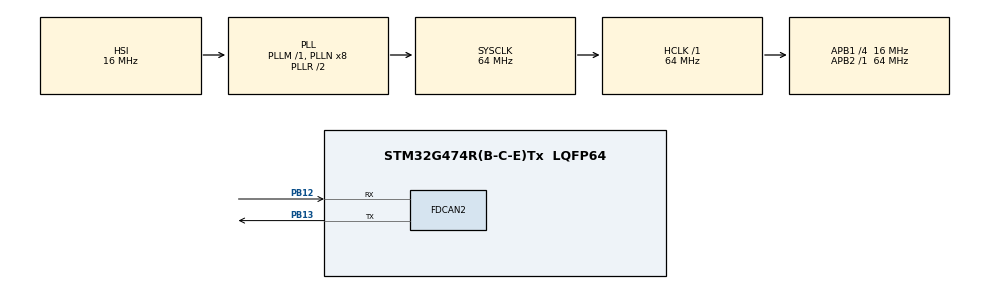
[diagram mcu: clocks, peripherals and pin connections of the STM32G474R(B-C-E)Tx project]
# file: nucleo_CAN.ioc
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FDCAN2.CalculateBaudRateNominal=500000
FDCAN2.CalculateTimeBitNominal=2000
FDCAN2.CalculateTimeQuantumNominal=125.0
FDCAN2.NominalPrescaler=2
FDCAN2.NominalTimeSeg1=13
FDCAN2.NominalTimeSeg2=2
Mcu.Family=STM32G4
Mcu.Name=STM32G474R(B-C-E)Tx
Mcu.Package=LQFP64
NUCLEO-G474RE.BUTTON=1
NUCLEO-G474RE.LD2=true
NUCLEO-G474RE.VCP=true
NVIC.EXTI15_10_IRQn=true\:0\:0\:false\:false\:true\:false\:true\:true
NVIC.PriorityGroup=NVIC_PRIORITYGROUP_4
PA13.GPIO_Label=T_SWDIO
PA13.Signal=SYS_JTMS-SWDIO
PA14.GPIO_Label=T_SWCLK
PA14.Signal=SYS_JTCK-SWCLK
PA2.Signal=LPUART1_TX
PA3.Signal=LPUART1_RX
PB12.Mode=FDCAN_Activate
PB12.Signal=FDCAN2_RX
PB13.Mode=FDCAN_Activate
PB13.Signal=FDCAN2_TX
PB3.GPIO_Label=T_SWO
PB3.Signal=SYS_JTDO-SWO
PC14-OSC32_IN.GPIO_Label=RCC_OSC32_IN
PC14-OSC32_IN.Signal=RCC_OSC32_IN
PC15-OSC32_OUT.GPIO_Label=RCC_OSC32_OUT
PC15-OSC32_OUT.Signal=RCC_OSC32_OUT
PF0-OSC_IN.GPIO_Label=RCC_OSC_IN
PF0-OSC_IN.Signal=RCC_OSC_IN
PF1-OSC_OUT.GPIO_Label=RCC_OSC_OUT
PF1-OSC_OUT.Signal=RCC_OSC_OUT
ProjectManager.HeapSize=0x200
ProjectManager.StackSize=0x400
ProjectManager.TargetToolchain=STM32CubeIDE
RCC.ADC12Freq_Value=64000000
RCC.ADC345Freq_Value=64000000
RCC.AHBFreq_Value=64000000
RCC.APB1CLKDivider=RCC_HCLK_DIV4
RCC.APB1Freq_Value=16000000
RCC.APB1TimFreq_Value=32000000
RCC.APB2Freq_Value=64000000
RCC.APB2TimFreq_Value=64000000
RCC.CortexFreq_Value=64000000
RCC.EXTERNAL_CLOCK_VALUE=12288000
RCC.HCLKFreq_Value=64000000
RCC.HSE_VALUE=24000000
RCC.HSI48_VALUE=48000000
RCC.HSI_VALUE=16000000
RCC.LSE_VALUE=32768
RCC.RTCClockSelection=RCC_RTCCLKSOURCE_LSE
RCC.SYSCLKFreq_VALUE=64000000
RCC.SYSCLKSource=RCC_SYSCLKSOURCE_PLLCLK
RCC.USBFreq_Value=64000000
RCC.VCOOutputFreq_Value=128000000
VP_NUCLEO-G474RE_VS_BSP_COMMON.Mode=COMMON
VP_SYS_VS_DBSignals.Mode=DisableDeadBatterySignals
board=NUCLEO-G474RE

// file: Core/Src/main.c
/* USER CODE BEGIN Header */
/**
  ******************************************************************************
  * @file           : main.c
  * @brief          : Main program body
  ******************************************************************************
  * @attention
  *
  * Copyright (c) 2026 STMicroelectronics.
  * All rights reserved.
  *
  * This software is licensed under terms that can be found in the LICENSE file
  * in the root directory of this software component.
  * If no LICENSE file comes with this software, it is provided AS-IS.
  *
  ******************************************************************************
  */
/* USER CODE END Header */
#include "main.h"

/* USER CODE BEGIN Includes */

#include <stdio.h>
#include <string.h>
/* USER CODE END Includes */

COM_InitTypeDef BspCOMInit;
FDCAN_HandleTypeDef hfdcan2;

/* USER CODE BEGIN PV */
FDCAN_TxHeaderTypeDef TxHeader;
uint8_t TxData[8] = {0};
uint8_t counter = 0;
/* USER CODE END PV */

void SystemClock_Config(void);
static void MX_GPIO_Init(void);
static void MX_FDCAN2_Init(void);

int main(void)
{

  /* MCU Configuration--------------------------------------------------------*/

  /* Reset of all peripherals, Initializes the Flash interface and the Systick. */
  HAL_Init();

  /* Configure the system clock */
  SystemClock_Config();

  /* Initialize all configured peripherals */
  MX_GPIO_Init();
  MX_FDCAN2_Init();
  /* USER CODE BEGIN 2 */
  HAL_Delay(3000);  /* let USB CDC enumerate */

    TxHeader.Identifier          = 0x100;
    TxHeader.IdType              = FDCAN_STANDARD_ID;
    TxHeader.TxFrameType         = FDCAN_DATA_FRAME;
    TxHeader.DataLength          = FDCAN_DLC_BYTES_8;
    TxHeader.ErrorStateIndicator = FDCAN_ESI_ACTIVE;
    TxHeader.BitRateSwitch       = FDCAN_BRS_OFF;
    TxHeader.FDFormat            = FDCAN_CLASSIC_CAN;
    TxHeader.TxEventFifoControl  = FDCAN_NO_TX_EVENTS;
    TxHeader.MessageMarker       = 0;

    if (HAL_FDCAN_Start(&hfdcan2) != HAL_OK) {
      printf("FAIL: FDCAN Start\r\n");
      HAL_Delay(100);
    } else {
      printf("FDCAN2 started — transmitting...\r\n");
      HAL_Delay(100);
    }
  /* USER CODE END 2 */

  /* Initialize led */
  BSP_LED_Init(LED_GREEN);

  /* Initialize USER push-button, will be used to trigger an interrupt each time it's pressed.*/
  BSP_PB_Init(BUTTON_USER, BUTTON_MODE_EXTI);

  /* Initialize COM1 port (115200, 8 bits (7-bit data + 1 stop bit), no parity */
  BspCOMInit.BaudRate   = 115200;
  BspCOMInit.WordLength = COM_WORDLENGTH_8B;
  BspCOMInit.StopBits   = COM_STOPBITS_1;
  BspCOMInit.Parity     = COM_PARITY_NONE;
  BspCOMInit.HwFlowCtl  = COM_HWCONTROL_NONE;
  if (BSP_COM_Init(COM1, &BspCOMInit) != BSP_ERROR_NONE)
  {
    Error_Handler();
  }

  /* Infinite loop */
  while (1)
  {

    /* USER CODE BEGIN 3 */
	  /* Fill dummy data — byte 0 counts up so you can see it changing */
	  	  	    TxData[0] = counter;
	  	  	    TxData[1] = 0xAA;
	  	  	    TxData[2] = 0xBB;
	  	  	    TxData[3] = 0xCC;
	  	  	    TxData[4] = 0xDD;
	  	  	    TxData[5] = 0xEE;
	  	  	    TxData[6] = 0xFF;
	  	  	    TxData[7] = counter;

	  	  	    /* Attempt to send */

	  	  	    HAL_StatusTypeDef whatsTheError = HAL_FDCAN_AddMessageToTxFifoQ(&hfdcan2, &TxHeader, TxData);
	  	  	    printf("%d\r\n", whatsTheError);

	  	  	    if (whatsTheError == HAL_OK) {
	  	  	      printf("TX OK  | counter=%d\r\n", counter);
	  	  	    } else {
	  	  	    	printf("TX FAIL| counter=%d\r\n", counter);
	  	  	    }

	  	  	    counter++;
	  	  	    HAL_Delay(500);  /* Send every 500 ms */

	    }
  }
  /* USER CODE END 3 */

void SystemClock_Config(void)
{
  RCC_OscInitTypeDef RCC_OscInitStruct = {0};
  RCC_ClkInitTypeDef RCC_ClkInitStruct = {0};

  /** Configure the main internal regulator output voltage
  */
  HAL_PWREx_ControlVoltageScaling(PWR_REGULATOR_VOLTAGE_SCALE1);

  /** Initializes the RCC Oscillators according to the specified parameters
  * in the RCC_OscInitTypeDef structure.
  */
  RCC_OscInitStruct.OscillatorType = RCC_OSCILLATORTYPE_HSI;
  RCC_OscInitStruct.HSIState = RCC_HSI_ON;
  RCC_OscInitStruct.HSICalibrationValue = RCC_HSICALIBRATION_DEFAULT;
  RCC_OscInitStruct.PLL.PLLState = RCC_PLL_ON;
  RCC_OscInitStruct.PLL.PLLSource = RCC_PLLSOURCE_HSI;
  RCC_OscInitStruct.PLL.PLLM = RCC_PLLM_DIV1;
  RCC_OscInitStruct.PLL.PLLN = 8;
  RCC_OscInitStruct.PLL.PLLP = RCC_PLLP_DIV2;
  RCC_OscInitStruct.PLL.PLLQ = RCC_PLLQ_DIV2;
  RCC_OscInitStruct.PLL.PLLR = RCC_PLLR_DIV2;
  if (HAL_RCC_OscConfig(&RCC_OscInitStruct) != HAL_OK)
  {
    Error_Handler();
  }

  /** Initializes the CPU, AHB and APB buses clocks
  */
  RCC_ClkInitStruct.ClockType = RCC_CLOCKTYPE_HCLK|RCC_CLOCKTYPE_SYSCLK
                              |RCC_CLOCKTYPE_PCLK1|RCC_CLOCKTYPE_PCLK2;
  RCC_ClkInitStruct.SYSCLKSource = RCC_SYSCLKSOURCE_PLLCLK;
  RCC_ClkInitStruct.AHBCLKDivider = RCC_SYSCLK_DIV1;
  RCC_ClkInitStruct.APB1CLKDivider = RCC_HCLK_DIV4;
  RCC_ClkInitStruct.APB2CLKDivider = RCC_HCLK_DIV1;

  if (HAL_RCC_ClockConfig(&RCC_ClkInitStruct, FLASH_LATENCY_2) != HAL_OK)
  {
    Error_Handler();
  }
}

static void MX_FDCAN2_Init(void)
{

  hfdcan2.Instance = FDCAN2;
  hfdcan2.Init.ClockDivider = FDCAN_CLOCK_DIV1;
  hfdcan2.Init.FrameFormat = FDCAN_FRAME_CLASSIC;
  hfdcan2.Init.Mode = FDCAN_MODE_NORMAL;
  hfdcan2.Init.AutoRetransmission = DISABLE;
  hfdcan2.Init.TransmitPause = DISABLE;
  hfdcan2.Init.ProtocolException = DISABLE;
  hfdcan2.Init.NominalPrescaler = 2;
  hfdcan2.Init.NominalSyncJumpWidth = 1;
  hfdcan2.Init.NominalTimeSeg1 = 13;
  hfdcan2.Init.NominalTimeSeg2 = 2;
  hfdcan2.Init.DataPrescaler = 1;
  hfdcan2.Init.DataSyncJumpWidth = 1;
  hfdcan2.Init.DataTimeSeg1 = 1;
  hfdcan2.Init.DataTimeSeg2 = 1;
  hfdcan2.Init.StdFiltersNbr = 0;
  hfdcan2.Init.ExtFiltersNbr = 0;
  hfdcan2.Init.TxFifoQueueMode = FDCAN_TX_FIFO_OPERATION;
  if (HAL_FDCAN_Init(&hfdcan2) != HAL_OK)
  {
    Error_Handler();
  }

}

static void MX_GPIO_Init(void)
{

  /* GPIO Ports Clock Enable */
  __HAL_RCC_GPIOC_CLK_ENABLE();
  __HAL_RCC_GPIOF_CLK_ENABLE();
  __HAL_RCC_GPIOB_CLK_ENABLE();
  __HAL_RCC_GPIOA_CLK_ENABLE();

}

void Error_Handler(void)
{
  __disable_irq();
  while (1)
  {
  }
}
